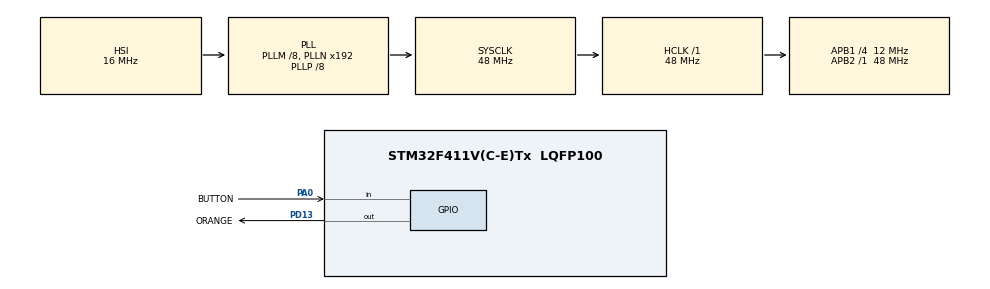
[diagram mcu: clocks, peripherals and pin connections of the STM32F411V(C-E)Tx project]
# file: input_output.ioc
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Mcu.Family=STM32F4
RCC.CortexFreq_Value=48000000
RCC.APB1CLKDivider=RCC_HCLK_DIV4
RCC.SYSCLKSource=RCC_SYSCLKSOURCE_PLLCLK
ProjectManager.StackSize=0x400
PA0-WKUP.GPIO_Label=BUTTON
PA0-WKUP.Signal=GPIO_Input
PA13.Signal=SYS_JTMS-SWDIO
PD13.Signal=GPIO_Output
ProjectManager.TargetToolchain=Makefile
RCC.HCLKFreq_Value=48000000
RCC.APB2TimFreq_Value=48000000
RCC.LSE_VALUE=32768
RCC.AHBFreq_Value=48000000
RCC.HSE_VALUE=8000000
board=STM32F411E-DISCO
RCC.VCOOutputFreq_Value=384000000
RCC.APB2Freq_Value=48000000
PA14.Mode=Serial_Wire
PA13.Mode=Serial_Wire
Mcu.Name=STM32F411V(C-E)Tx
RCC.48MHZClocksFreq_Value=48000000
RCC.SYSCLKFreq_VALUE=48000000
PD13.GPIO_Label=ORANGE
Mcu.Package=LQFP100
PA14.Signal=SYS_JTCK-SWCLK
ProjectManager.HeapSize=0x200
RCC.HSI_VALUE=16000000
RCC.PLLP=RCC_PLLP_DIV8
RCC.PLLQ=8
NVIC.PriorityGroup=NVIC_PRIORITYGROUP_0
RCC.PLLM=8
RCC.APB1TimFreq_Value=24000000
RCC.APB1Freq_Value=12000000
RCC.PLLI2SN=200
RCC.PLLI2SM=5

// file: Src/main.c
/* USER CODE BEGIN Header */
/**
  ******************************************************************************
  * @file           : main.c
  * @brief          : Main program body
  ******************************************************************************
  * @attention
  *
  * <h2><center>&copy; Copyright (c) 2020 STMicroelectronics.
  * All rights reserved.</center></h2>
  *
  * This software component is licensed by ST under BSD 3-Clause license,
  * the "License"; You may not use this file except in compliance with the
  * License. You may obtain a copy of the License at:
  *                        opensource.org/licenses/BSD-3-Clause
  *
  ******************************************************************************
  */
/* USER CODE END Header */

#include "main.h"
#include "stdint.h"

void SystemClock_Config(void);
static void MX_GPIO_Init(void);

int main(void)
{
  /* USER CODE BEGIN 1 */
  uint32_t button_status = 0;
  /* USER CODE END 1 */

  /* MCU Configuration--------------------------------------------------------*/

  /* Reset of all peripherals, Initializes the Flash interface and the Systick. */
  HAL_Init();

  /* Configure the system clock */
  SystemClock_Config();

  /* Initialize all configured peripherals */
  MX_GPIO_Init();

  /* Infinite loop */
  /* USER CODE BEGIN WHILE */
  while (1)
  {
    button_status = HAL_GPIO_ReadPin(GPIOA, BUTTON_Pin);
    HAL_GPIO_WritePin(GPIOD, ORANGE_Pin, button_status);
  }
  /* USER CODE END 3 */
}

void SystemClock_Config(void)
{
  RCC_OscInitTypeDef RCC_OscInitStruct = {0};
  RCC_ClkInitTypeDef RCC_ClkInitStruct = {0};

  /** Configure the main internal regulator output voltage
  */
  __HAL_RCC_PWR_CLK_ENABLE();
  __HAL_PWR_VOLTAGESCALING_CONFIG(PWR_REGULATOR_VOLTAGE_SCALE1);
  /** Initializes the CPU, AHB and APB busses clocks
  */
  RCC_OscInitStruct.OscillatorType = RCC_OSCILLATORTYPE_HSI;
  RCC_OscInitStruct.HSIState = RCC_HSI_ON;
  RCC_OscInitStruct.HSICalibrationValue = RCC_HSICALIBRATION_DEFAULT;
  RCC_OscInitStruct.PLL.PLLState = RCC_PLL_ON;
  RCC_OscInitStruct.PLL.PLLSource = RCC_PLLSOURCE_HSI;
  RCC_OscInitStruct.PLL.PLLM = 8;
  RCC_OscInitStruct.PLL.PLLN = 192;
  RCC_OscInitStruct.PLL.PLLP = RCC_PLLP_DIV8;
  RCC_OscInitStruct.PLL.PLLQ = 8;
  if (HAL_RCC_OscConfig(&RCC_OscInitStruct) != HAL_OK)
  {
    Error_Handler();
  }
  /** Initializes the CPU, AHB and APB busses clocks
  */
  RCC_ClkInitStruct.ClockType = RCC_CLOCKTYPE_HCLK|RCC_CLOCKTYPE_SYSCLK
                              |RCC_CLOCKTYPE_PCLK1|RCC_CLOCKTYPE_PCLK2;
  RCC_ClkInitStruct.SYSCLKSource = RCC_SYSCLKSOURCE_PLLCLK;
  RCC_ClkInitStruct.AHBCLKDivider = RCC_SYSCLK_DIV1;
  RCC_ClkInitStruct.APB1CLKDivider = RCC_HCLK_DIV4;
  RCC_ClkInitStruct.APB2CLKDivider = RCC_HCLK_DIV1;

  if (HAL_RCC_ClockConfig(&RCC_ClkInitStruct, FLASH_LATENCY_1) != HAL_OK)
  {
    Error_Handler();
  }
}

static void MX_GPIO_Init(void)
{
  GPIO_InitTypeDef GPIO_InitStruct = {0};

  /* GPIO Ports Clock Enable */
  __HAL_RCC_GPIOA_CLK_ENABLE();
  __HAL_RCC_GPIOD_CLK_ENABLE();

  /*Configure GPIO pin Output Level */
  HAL_GPIO_WritePin(ORANGE_GPIO_Port, ORANGE_Pin, GPIO_PIN_RESET);

  /*Configure GPIO pin : BUTTON_Pin */
  GPIO_InitStruct.Pin = BUTTON_Pin;
  GPIO_InitStruct.Mode = GPIO_MODE_INPUT;
  GPIO_InitStruct.Pull = GPIO_NOPULL;
  HAL_GPIO_Init(BUTTON_GPIO_Port, &GPIO_InitStruct);

  /*Configure GPIO pin : ORANGE_Pin */
  GPIO_InitStruct.Pin = ORANGE_Pin;
  GPIO_InitStruct.Mode = GPIO_MODE_OUTPUT_PP;
  GPIO_InitStruct.Pull = GPIO_NOPULL;
  GPIO_InitStruct.Speed = GPIO_SPEED_FREQ_LOW;
  HAL_GPIO_Init(ORANGE_GPIO_Port, &GPIO_InitStruct);

}

void Error_Handler(void)
{
}

/************************ (C) COPYRIGHT STMicroelectronics *****END OF FILE****/
